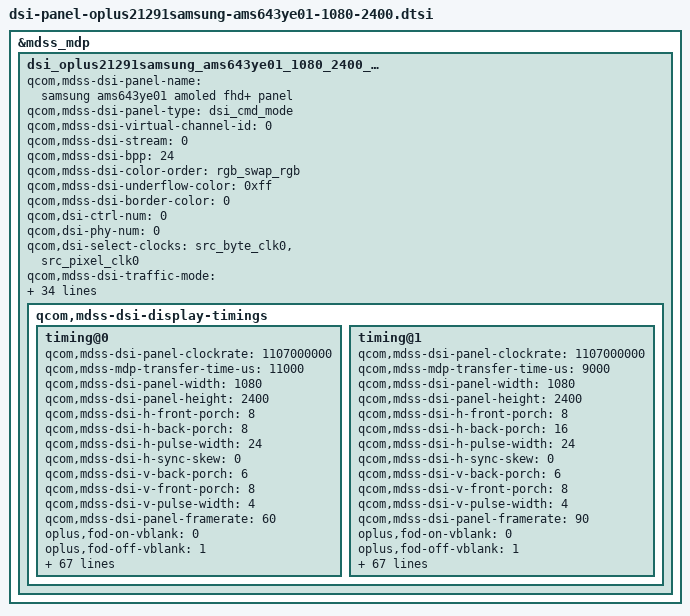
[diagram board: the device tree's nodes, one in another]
/* Copyright (c) 2014-2018, The Linux Foundation. All rights reserved.
 *
 * This program is free software; you can redistribute it and/or modify
 * it under the terms of the GNU General Public License version 2 and
 * only version 2 as published by the Free Software Foundation.
 *
 * This program is distributed in the hope that it will be useful,
 * but WITHOUT ANY WARRANTY; without even the implied warranty of
 * MERCHANTABILITY or FITNESS FOR A PARTICULAR PURPOSE.  See the
 * GNU General Public License for more details.
 */

&mdss_mdp {
	dsi_oplus21291samsung_ams643ye01_1080_2400_cmd: qcom,mdss_dsi_oplus21291samsung_ams643ye01_1080_2400_cmd {
		qcom,mdss-dsi-panel-name =
		  "samsung ams643ye01 amoled fhd+ panel";
		qcom,mdss-dsi-panel-type = "dsi_cmd_mode";
		qcom,mdss-dsi-virtual-channel-id = <0>;
		qcom,mdss-dsi-stream = <0>;
		qcom,mdss-dsi-bpp = <24>;
		qcom,mdss-dsi-color-order = "rgb_swap_rgb";
		qcom,mdss-dsi-underflow-color = <0xff>;
		qcom,mdss-dsi-border-color = <0>;

		qcom,dsi-ctrl-num = <0>;
		qcom,dsi-phy-num = <0>;
		qcom,dsi-select-clocks = "src_byte_clk0", "src_pixel_clk0";

		qcom,mdss-dsi-traffic-mode = "non_burst_sync_event";
		qcom,mdss-dsi-lane-map = "lane_map_0123";
		qcom,mdss-dsi-bllp-eof-power-mode;
		qcom,mdss-dsi-bllp-power-mode;
		qcom,mdss-dsi-lane-0-state;
		qcom,mdss-dsi-lane-1-state;
		qcom,mdss-dsi-lane-2-state;
		qcom,mdss-dsi-lane-3-state;
		qcom,mdss-dsi-dma-trigger = "trigger_sw";
		qcom,mdss-dsi-mdp-trigger = "none";
		qcom,mdss-dsi-reset-sequence = <1 10>, <0 10>, <1 10>;
		qcom,mdss-dsi-te-pin-select = <1>;
		qcom,mdss-dsi-te-dcs-command = <1>;
		qcom,mdss-dsi-te-check-enable;
		qcom,mdss-dsi-te-using-te-pin;
		qcom,mdss-dsi-wr-mem-start = <0x2c>;
		qcom,mdss-dsi-wr-mem-continue = <0x3c>;
		qcom,mdss-dsi-panel-hdr-enabled;
		qcom,mdss-dsi-panel-hdr-color-primaries = <15000 15500 34000
			16000 13250 34500 7500 3000>;
		qcom,mdss-dsi-panel-peak-brightness = <4300000>;
		qcom,mdss-dsi-panel-blackness-level = <1023>;
		qcom,mdss-pan-physical-width-dimension = <68>;
		qcom,mdss-pan-physical-height-dimension = <152>;
		qcom,esd-check-enabled;
		qcom,mdss-dsi-panel-status-check-mode = "reg_read";
		qcom,mdss-dsi-panel-status-command = [06 01 00 01 00 00 02 0A 00
							06 01 00 01 00 00 02 0E 00
							06 01 00 01 00 00 02 05 00];
		qcom,mdss-dsi-panel-status-command-state = "dsi_hs_mode";
		qcom,mdss-dsi-panel-status-value = <0x9F 0x80 0x00>;
		qcom,mdss-dsi-panel-status-read-length = <1 1 1>;

		qcom,mdss-dsi-display-timings {
			timing@0{
				qcom,mdss-dsi-panel-clockrate = <1107000000>;
				qcom,mdss-mdp-transfer-time-us = <11000>;
				qcom,mdss-dsi-panel-width = <1080>;
				qcom,mdss-dsi-panel-height = <2400>;
				qcom,mdss-dsi-h-front-porch = <8>;
				qcom,mdss-dsi-h-back-porch = <8>;
				qcom,mdss-dsi-h-pulse-width = <24>;
				qcom,mdss-dsi-h-sync-skew = <0>;
				qcom,mdss-dsi-v-back-porch = <6>;
				qcom,mdss-dsi-v-front-porch = <8>;
				qcom,mdss-dsi-v-pulse-width = <4>;
				qcom,mdss-dsi-panel-framerate = <60>;
				oplus,fod-on-vblank = <0>;
				oplus,fod-off-vblank = <1>;

				qcom,mdss-dsi-on-command = [
					/*PPS Setting*/
					39 01 00 00 00 00 81 9E
					11 00 00 89 30 80 09 60
					04 38 00 1E 02 1C 02 1C
					02 00 02 0E 00 20 02 E3
					00 07 00 0C 03 50 03 64
					18 00 10 F0 03 0C 20 00
					06 0B 0B 33 0E 1C 2A 38
					46 54 62 69 70 77 79 7B
					7D 7E 01 02 01 00 09 40
					09 BE 19 FC 19 FA 19 F8
					1A 38 1A 78 1A B6 2A F6
					2B 34 2B 74 3B 74 6B F4
					00 00 00 00 00 00 00 00
					00 00 00 00 00 00 00 00
					00 00 00 00 00 00 00 00
					00 00 00 00 00 00 00 00
					00 00 00 00 00 00 00 00
					15 01 00 00 00 00 02 C2 14
					15 01 00 00 00 00 02 9D 01
					/*OSC 167M*/
					39 01 00 00 00 00 03 F0 5A 5A
					39 01 00 00 00 00 03 FC 5A 5A
					39 01 00 00 00 00 03 B0 66 C5
					39 01 00 00 00 00 03 C5 00 8C
					39 01 00 00 00 00 03 B0 2A C5
					39 01 00 00 00 00 05 C5 0D 10 80 45
					39 01 00 00 00 00 03 B0 3E C5
					39 01 00 00 00 00 03 C5 4D 3D
					39 01 00 00 00 00 03 F0 A5 A5
					39 01 00 00 00 00 03 FC A5 A5
					05 01 00 00 80 00 01 11
					/* CASET/PASET Setting */
					39 01 00 00 00 00 05 2A 00 00 04 37
					39 01 00 00 00 00 05 2B 00 00 09 5F
					/* FQ CON Setting*/
					39 01 00 00 00 00 03 F0 5A 5A
					39 01 00 00 00 00 03 B0 27 F2
					15 01 00 00 00 00 02 F2 00
					39 01 00 00 00 00 03 F0 A5 A5
					/* TE vsync ON */
					15 01 00 00 00 00 02 35 00
					/*Frequency Change*/
					39 01 00 00 00 00 03 F0 5A 5A
					39 01 00 00 00 00 03 60 00 00
					39 01 00 00 00 00 02 F7 0F
					39 01 00 00 00 00 03 F0 A5 A5
					15 01 00 00 00 00 02 53 20
				];
				qcom,mdss-dsi-post-on-backlight = [
					39 01 00 00 00 00 03 F0 5A 5A
					39 01 00 00 12 00 03 F0 A5 A5
					/* Display On*/
					05 01 00 00 00 00 01 29
				];
				qcom,mdss-dsi-timing-switch-command = [
					/* 60hz Transition */
					39 01 00 00 00 00 03 F0 5A 5A
					39 01 00 00 00 00 03 60 00 00
					39 01 00 00 00 00 02 F7 0F
					39 01 00 00 00 00 03 F0 A5 A5
				];
				qcom,mdss-dsi-off-command = [
					05 01 00 00 0A 00 01 28
					05 01 00 00 96 00 01 10
				];
				qcom,mdss-dsi-lp1-command = [
					05 01 00 00 25 00 01 28
					39 01 00 00 00 00 03 F0 5A 5A
					39 01 00 00 00 00 02 91 01
					15 01 00 00 00 00 02 53 25
					15 01 00 00 00 00 02 BB 1D
					39 01 00 00 00 00 03 F0 A5 A5
				];
				qcom,mdss-dsi-nolp-command = [
					/*HBM OFF */
					39 00 00 00 00 00 03 F0 5A 5A
					39 00 00 00 00 00 03 B0 02 90
					15 00 00 00 00 00 02 90 1C
					39 00 00 00 00 00 02 91 02
					15 00 00 00 00 00 02 53 20
					39 01 00 00 00 00 03 F0 A5 A5
				];
				qcom,mdss-dsi-aod-high-mode-command = [
					15 01 00 00 00 00 02 53 24
				];
				qcom,mdss-dsi-aod-low-mode-command = [
					15 01 00 00 00 00 02 53 25
				];
				qcom,mdss-dsi-aod-hbm-on-command = [
					/* AOD off */
					39 00 00 00 00 00 03 F0 5A 5A
					39 00 00 00 00 00 02 91 02
					15 00 00 00 00 00 02 53 20
					39 00 00 00 00 00 03 F0 A5 A5
					/* HBM Mode ON */
					39 00 00 00 00 00 03 F0 5A 5A
					39 00 00 00 00 00 03 B0 02 90
					15 00 00 00 00 00 02 90 14
					/* 0xE0 Normal transition */
					39 00 00 00 00 00 02 53 E0
					39 00 00 00 00 00 03 51 0F FF
					39 01 00 00 00 00 03 F0 A5 A5
				];
				qcom,mdss-dsi-hbm-on-command = [
					/* HBM Mode ON */
					39 01 00 00 00 00 03 F0 5A 5A
					39 01 00 00 00 00 03 B0 02 90
					15 01 00 00 00 00 02 90 14
					/* 0xE0 Normal transition */
					39 01 00 00 00 00 02 53 E0
					39 01 00 00 00 00 03 51 0F FF
					39 01 00 00 00 00 03 F0 A5 A5
				];
				qcom,mdss-dsi-normal-hbm-on-command = [
					/* HBM Mode ON */
					39 01 00 00 00 00 03 F0 5A 5A
					39 01 00 00 00 00 03 B0 02 90
					15 01 00 00 00 00 02 90 14
					/* 0xE0 Normal transition */
					39 01 00 00 00 00 02 53 E0
					39 01 00 00 00 00 03 51 0F FF
					39 01 00 00 00 00 03 F0 A5 A5
				];
				qcom,mdss-dsi-hbm-off-command = [
					/*HBM OFF */
					39 01 00 00 00 00 03 F0 5A 5A
					39 01 00 00 00 00 03 B0 02 90
					15 01 00 00 00 00 02 90 1C
					15 01 00 00 00 00 02 53 20
					39 01 00 00 00 00 03 F0 A5 A5
				];
				qcom,mdss-dsi-aod-hbm-off-command = [
					/*HBM OFF */
					39 01 00 00 00 00 03 F0 5A 5A
					39 01 00 00 00 00 03 B0 02 90
					15 01 00 00 00 00 02 90 1C
					15 01 00 00 00 00 02 53 24
					39 01 00 00 00 00 03 F0 A5 A5
					/*AOD on */
					39 01 00 00 00 00 03 F0 5A 5A
					39 01 00 00 00 00 02 91 01
					15 01 00 00 00 00 02 53 24
					15 01 00 00 00 00 02 BB 1D
					39 01 00 00 00 00 03 F0 A5 A5
				];
				qcom,mdss-dsi-seed-off-command = [
					/* CRC OFF */
					39 00 00 00 00 00 03 F0 5A 5A
					15 00 00 00 00 00 02 5D 00
					39 00 00 00 00 00 02 62 01
					39 01 00 00 00 00 03 F0 A5 A5
				];
				qcom,mdss-dsi-seed-0-command = [
					/* SEED CRC Setting */
					39 00 00 00 00 00 03 F0 5A 5A
					39 00 00 00 00 00 02 5D 86
					/* SEED CRC ON */
					39 00 00 00 00 00 02 62 00
					/* SEED CRC DCI-P3 */
					39 00 00 00 00 00 03 B0 2B 62
					39 00 00 00 00 00 16 62 D8 00 04 00 FF 02 00 00 FF 18 FF E4 FB 00 F0 F6 EA 01 FF FF FF
					39 01 00 00 00 00 03 F0 A5 A5
				];
				qcom,mdss-dsi-seed-1-command = [
					/* SEED CRC Setting */
					39 00 00 00 00 00 03 F0 5A 5A
					39 00 00 00 00 00 02 5D 06
					/* SEED CRC ON */
					39 00 00 00 00 00 02 62 00
					/* SEED CRC sRGB */
					39 00 00 00 00 00 03 B0 01 62
					39 00 00 00 00 00 16 62 B0 02 06 3A D7 17 07 05 B2 48 F2 DC C4 07 C8 E9 E9 1D FF FF FF
					39 01 00 00 00 00 03 F0 A5 A5
				];
				qcom,mdss-dsi-seed-2-command = [
					/* SEED CRC Setting */
					39 00 00 00 00 00 03 F0 5A 5A
					39 00 00 00 00 00 02 5D 46
					/* SEED CRC ON */
					39 00 00 00 00 00 02 62 00
					/* SEED CRC Adobe */
					39 00 00 00 00 00 03 B0 16 62
					39 00 00 00 00 00 16 62 D8 00 04 00 FF 02 00 00 FF 18 FF E4 FB 00 F0 F6 EA 01 FF FF FF
					39 01 00 00 00 00 03 F0 A5 A5
				];
				qcom,mdss-dsi-osc-clk-mode0-command = [
					/*OSC 167M*/
					39 01 00 00 00 00 03 F0 5A 5A
					39 01 00 00 00 00 03 FC 5A 5A
					39 01 00 00 00 00 03 B0 66 C5
					39 01 00 00 00 00 03 C5 00 8C
					39 01 00 00 00 00 03 B0 2A C5
					39 01 00 00 00 00 05 C5 0D 10 80 45
					39 01 00 00 00 00 03 B0 3E C5
					39 01 00 00 00 00 03 C5 4D 3D
					39 01 00 00 00 00 03 F0 A5 A5
					39 01 00 00 00 00 03 FC A5 A5
				];
				qcom,mdss-dsi-osc-clk-mode1-command = [
					/*OSC 169M*/
					39 01 00 00 00 00 03 F0 5A 5A
					39 01 00 00 00 00 03 FC 5A 5A
					39 01 00 00 00 00 03 B0 66 C5
					39 01 00 00 00 00 03 C5 00 8C
					39 01 00 00 00 00 03 B0 2A C5
					39 01 00 00 00 00 05 C5 0D 10 80 45
					39 01 00 00 00 00 03 B0 3E C5
					39 01 00 00 00 00 03 C5 4E 2A
					39 01 00 00 00 00 03 F0 A5 A5
					39 01 00 00 00 00 03 FC A5 A5
				];
				qcom,mdss-dsi-hbm-enter-switch-command = [
					39 01 00 00 00 00 03 F0 5A 5A
					39 01 00 00 11 00 03 51 07 FF
					39 01 00 00 00 00 03 91 02 00
					15 00 00 00 00 00 02 53 E0
					39 01 00 00 00 00 03 51 08 00
					39 01 00 00 00 00 03 F0 A5 A5
				];
				qcom,mdss-dsi-hbm-exit-switch-command = [
					39 01 00 00 00 00 03 F0 5A 5A
					15 00 00 00 00 00 02 53 20
					39 01 00 00 11 00 03 51 07 FF
					39 00 00 00 00 00 03 91 02 01
					39 01 00 00 00 00 03 F0 A5 A5
				];

				qcom,mdss-dsi-aod-hbm-on-command-state = "dsi_hs_mode";
				qcom,mdss-dsi-aod-hbm-off-command-state = "dsi_hs_mode";
				qcom,mdss-dsi-seed-off-command-state = "dsi_hs_mode";
				qcom,mdss-dsi-seed-0-command-state = "dsi_hs_mode";
				qcom,mdss-dsi-seed-1-command-state = "dsi_hs_mode";
				qcom,mdss-dsi-seed-2-command-state = "dsi_hs_mode";
				qcom,mdss-dsi-lp1-command-state = "dsi_hs_mode";
				qcom,mdss-dsi-nolp-command-state = "dsi_hs_mode";
				qcom,mdss-dsi-post-on-backlight-state = "dsi_hs_mode";
				qcom,mdss-dsi-on-command-state = "dsi_hs_mode";
				qcom,mdss-dsi-off-command-state = "dsi_hs_mode";
				qcom,compression-mode = "dsc";
				qcom,mdss-dsc-slice-height = <30>;
				qcom,mdss-dsc-slice-width = <540>;
				qcom,mdss-dsc-slice-per-pkt = <2>;
				qcom,mdss-dsc-bit-per-component = <8>;
				qcom,mdss-dsc-bit-per-pixel = <8>;
				qcom,mdss-dsc-block-prediction-enable;
			};

			timing@1{
				qcom,mdss-dsi-panel-clockrate = <1107000000>;
				qcom,mdss-mdp-transfer-time-us = <9000>;
				qcom,mdss-dsi-panel-width = <1080>;
				qcom,mdss-dsi-panel-height = <2400>;
				qcom,mdss-dsi-h-front-porch = <8>;
				qcom,mdss-dsi-h-back-porch = <16>;
				qcom,mdss-dsi-h-pulse-width = <24>;
				qcom,mdss-dsi-h-sync-skew = <0>;
				qcom,mdss-dsi-v-back-porch = <6>;
				qcom,mdss-dsi-v-front-porch = <8>;
				qcom,mdss-dsi-v-pulse-width = <4>;
				qcom,mdss-dsi-panel-framerate = <90>;
				oplus,fod-on-vblank = <0>;
				oplus,fod-off-vblank = <1>;
				qcom,mdss-dsi-on-command = [
					/*PPS Setting*/
					39 01 00 00 00 00 81 9E
					11 00 00 89 30 80 09 60
					04 38 00 1E 02 1C 02 1C
					02 00 02 0E 00 20 02 E3
					00 07 00 0C 03 50 03 64
					18 00 10 F0 03 0C 20 00
					06 0B 0B 33 0E 1C 2A 38
					46 54 62 69 70 77 79 7B
					7D 7E 01 02 01 00 09 40
					09 BE 19 FC 19 FA 19 F8
					1A 38 1A 78 1A B6 2A F6
					2B 34 2B 74 3B 74 6B F4
					00 00 00 00 00 00 00 00
					00 00 00 00 00 00 00 00
					00 00 00 00 00 00 00 00
					00 00 00 00 00 00 00 00
					00 00 00 00 00 00 00 00
					15 01 00 00 00 00 02 C2 14
					15 01 00 00 00 00 02 9D 01
					/*OSC 167M*/
					39 01 00 00 00 00 03 F0 5A 5A
					39 01 00 00 00 00 03 FC 5A 5A
					39 01 00 00 00 00 03 B0 66 C5
					39 01 00 00 00 00 03 C5 00 8C
					39 01 00 00 00 00 03 B0 2A C5
					39 01 00 00 00 00 05 C5 0D 10 80 45
					39 01 00 00 00 00 03 B0 3E C5
					39 01 00 00 00 00 03 C5 4D 3D
					39 01 00 00 00 00 03 F0 A5 A5
					39 01 00 00 00 00 03 FC A5 A5
					05 01 00 00 80 00 01 11
					/* CASET/PASET Setting */
					39 01 00 00 00 00 05 2A 00 00 04 37
					39 01 00 00 00 00 05 2B 00 00 09 5F
					/* FQ CON Setting*/
					39 01 00 00 00 00 03 F0 5A 5A
					39 01 00 00 00 00 03 B0 27 F2
					15 01 00 00 00 00 02 F2 00
					39 01 00 00 00 00 03 F0 A5 A5
					/* TE vsync ON */
					15 01 00 00 00 00 02 35 00
					/*Frequency Change*/
					39 01 00 00 00 00 03 F0 5A 5A
					39 01 00 00 00 00 03 60 08 00
					39 01 00 00 00 00 02 F7 0F
					39 01 00 00 00 00 03 F0 A5 A5
					15 01 00 00 00 00 02 53 20
				];
				qcom,mdss-dsi-post-on-backlight = [
					/* Display On*/
					05 01 00 00 00 00 01 29
				];
				qcom,mdss-dsi-timing-switch-command = [
					/* 90hz Transition */
					39 01 00 00 00 00 03 F0 5A 5A
					39 01 00 00 00 00 03 60 08 00
					39 01 00 00 00 00 02 F7 0F
					39 01 00 00 00 00 03 F0 A5 A5
				];
				qcom,mdss-dsi-off-command = [
					05 01 00 00 0A 00 01 28
					05 01 00 00 96 00 01 10
				];
				qcom,mdss-dsi-lp1-command = [
					05 01 00 00 25 00 01 28
					39 01 00 00 00 00 03 F0 5A 5A
					39 01 00 00 00 00 02 91 01
					15 01 00 00 00 00 02 53 25
					15 01 00 00 00 00 02 BB 1D
					39 01 00 00 00 00 03 F0 A5 A5
				];
				qcom,mdss-dsi-nolp-command = [
					/*HBM OFF */
					39 00 00 00 00 00 03 F0 5A 5A
					39 00 00 00 00 00 03 B0 02 90
					15 00 00 00 00 00 02 90 1C
					39 00 00 00 00 00 02 91 02
					15 00 00 00 00 00 02 53 20
					39 01 00 00 00 00 03 F0 A5 A5
				];
				qcom,mdss-dsi-aod-high-mode-command = [
					15 01 00 00 00 00 02 53 24
				];
				qcom,mdss-dsi-aod-low-mode-command = [
					15 01 00 00 00 00 02 53 25
				];
				qcom,mdss-dsi-aod-hbm-on-command = [
					/* AOD off */
					39 00 00 00 00 00 03 F0 5A 5A
					39 00 00 00 00 00 02 91 02
					15 00 00 00 00 00 02 53 20
					39 00 00 00 00 00 03 F0 A5 A5
					/* HBM Mode ON */
					39 00 00 00 00 00 03 F0 5A 5A
					39 00 00 00 00 00 03 B0 02 90
					15 00 00 00 00 00 02 90 14
					/* 0xE0 Normal transition */
					39 00 00 00 00 00 02 53 E0
					39 00 00 00 00 00 03 51 0F FF
					39 01 00 00 00 00 03 F0 A5 A5
				];
				qcom,mdss-dsi-hbm-on-command = [
					/* HBM Mode ON */
					39 01 00 00 00 00 03 F0 5A 5A
					39 01 00 00 00 00 03 B0 02 90
					15 01 00 00 00 00 02 90 14
					/* 0xE0 Normal transition */
					39 01 00 00 00 00 02 53 E0
					39 01 00 00 00 00 03 51 0F FF
					39 01 00 00 00 00 03 F0 A5 A5
				];
				qcom,mdss-dsi-normal-hbm-on-command = [
					/* HBM Mode ON */
					39 01 00 00 00 00 03 F0 5A 5A
					39 01 00 00 00 00 03 B0 02 90
					15 01 00 00 00 00 02 90 14
					/* 0xE0 Normal transition */
					39 01 00 00 00 00 02 53 E0
					39 01 00 00 00 00 03 51 0F FF
					39 01 00 00 00 00 03 F0 A5 A5
				];
				qcom,mdss-dsi-hbm-off-command = [
					39 01 00 00 00 00 03 F0 5A 5A
					39 01 00 00 00 00 03 B0 02 90
					15 01 00 00 00 00 02 90 1C
					39 01 00 00 00 00 02 91 02
					15 01 00 00 00 00 02 53 20
					39 01 00 00 00 00 03 F0 A5 A5
				];
				qcom,mdss-dsi-aod-hbm-off-command = [
					/*HBM OFF */
					39 01 00 00 00 00 03 F0 5A 5A
					39 01 00 00 00 00 03 B0 02 90
					15 01 00 00 00 00 02 90 1C
					15 01 00 00 00 00 02 53 25
					39 01 00 00 00 00 03 F0 A5 A5
					/*AOD on */
					39 01 00 00 00 00 03 F0 5A 5A
					39 01 00 00 00 00 02 91 01
					15 01 00 00 00 00 02 53 25
					15 01 00 00 00 00 02 BB 1D
					39 01 00 00 00 00 03 F0 A5 A5
				];
				qcom,mdss-dsi-seed-off-command = [
					/* CRC OFF */
					39 00 00 00 00 00 03 F0 5A 5A
					15 00 00 00 00 00 02 5D 00
					39 00 00 00 00 00 02 62 01
					39 01 00 00 00 00 03 F0 A5 A5
				];
				qcom,mdss-dsi-seed-0-command = [
					/* SEED CRC Setting */
					39 00 00 00 00 00 03 F0 5A 5A
					39 00 00 00 00 00 02 5D 86
					/* SEED CRC ON */
					39 00 00 00 00 00 02 62 00
					/* SEED CRC DCI-P3 */
					39 00 00 00 00 00 03 B0 2B 62
					39 00 00 00 00 00 16 62 D8 00 04 00 FF 02 00 00 FF 18 FF E4 FB 00 F0 F6 EA 01 FF FF FF
					39 01 00 00 00 00 03 F0 A5 A5
				];
				qcom,mdss-dsi-seed-1-command = [
					/* SEED CRC Setting */
					39 00 00 00 00 00 03 F0 5A 5A
					39 00 00 00 00 00 02 5D 06
					/* SEED CRC ON */
					39 00 00 00 00 00 02 62 00
					/* SEED CRC sRGB */
					39 00 00 00 00 00 03 B0 01 62
					39 00 00 00 00 00 16 62 B0 02 06 3A D7 17 07 05 B2 48 F2 DC C4 07 C8 E9 E9 1D FF FF FF
					39 01 00 00 00 00 03 F0 A5 A5
				];
				qcom,mdss-dsi-seed-2-command = [
					/* SEED CRC Setting */
					39 00 00 00 00 00 03 F0 5A 5A
					39 00 00 00 00 00 02 5D 46
					/* SEED CRC ON */
					39 00 00 00 00 00 02 62 00
					/* SEED CRC Adobe */
					39 00 00 00 00 00 03 B0 16 62
					39 00 00 00 00 00 16 62 D8 00 04 00 FF 02 00 00 FF 18 FF E4 FB 00 F0 F6 EA 01 FF FF FF
					39 01 00 00 00 00 03 F0 A5 A5
				];
				qcom,mdss-dsi-osc-clk-mode0-command = [
					/*OSC 167M*/
					39 01 00 00 00 00 03 F0 5A 5A
					39 01 00 00 00 00 03 FC 5A 5A
					39 01 00 00 00 00 03 B0 66 C5
					39 01 00 00 00 00 03 C5 00 8C
					39 01 00 00 00 00 03 B0 2A C5
					39 01 00 00 00 00 05 C5 0D 10 80 45
					39 01 00 00 00 00 03 B0 3E C5
					39 01 00 00 00 00 03 C5 4D 3D
					39 01 00 00 00 00 03 F0 A5 A5
					39 01 00 00 00 00 03 FC A5 A5
				];
				qcom,mdss-dsi-osc-clk-mode1-command = [
					/*OSC 169M*/
					39 01 00 00 00 00 03 F0 5A 5A
					39 01 00 00 00 00 03 FC 5A 5A
					39 01 00 00 00 00 03 B0 66 C5
					39 01 00 00 00 00 03 C5 00 8C
					39 01 00 00 00 00 03 B0 2A C5
					39 01 00 00 00 00 05 C5 0D 10 80 45
					39 01 00 00 00 00 03 B0 3E C5
					39 01 00 00 00 00 03 C5 4E 2A
					39 01 00 00 00 00 03 F0 A5 A5
					39 01 00 00 00 00 03 FC A5 A5
				];
				qcom,mdss-dsi-hbm-enter-switch-command = [
					39 01 00 00 00 00 03 F0 5A 5A
					39 01 00 00 0C 00 03 51 07 FF
					39 01 00 00 00 00 03 91 02 00
					15 00 00 00 00 00 02 53 E0
					39 01 00 00 00 00 03 51 08 00
					39 01 00 00 00 00 03 F0 A5 A5
				];
				qcom,mdss-dsi-hbm-exit-switch-command = [
					39 01 00 00 00 00 03 F0 5A 5A
					15 00 00 00 00 00 02 53 20
					39 01 00 00 0C 00 03 51 07 FF
					39 00 00 00 00 00 03 91 02 01
					39 01 00 00 00 00 03 F0 A5 A5
				];

				qcom,mdss-dsi-aod-hbm-on-command-state = "dsi_hs_mode";
				qcom,mdss-dsi-aod-hbm-off-command-state = "dsi_hs_mode";
				qcom,mdss-dsi-seed-off-command-state = "dsi_hs_mode";
				qcom,mdss-dsi-seed-0-command-state = "dsi_hs_mode";
				qcom,mdss-dsi-seed-1-command-state = "dsi_hs_mode";
				qcom,mdss-dsi-seed-2-command-state = "dsi_hs_mode";
				qcom,mdss-dsi-lp1-command-state = "dsi_hs_mode";
				qcom,mdss-dsi-nolp-command-state = "dsi_hs_mode";
				qcom,mdss-dsi-post-on-backlight-state = "dsi_hs_mode";
				qcom,mdss-dsi-on-command-state = "dsi_hs_mode";
				qcom,mdss-dsi-off-command-state = "dsi_hs_mode";
				qcom,compression-mode = "dsc";
				qcom,mdss-dsc-slice-height = <30>;
				qcom,mdss-dsc-slice-width = <540>;
				qcom,mdss-dsc-slice-per-pkt = <2>;
				qcom,mdss-dsc-bit-per-component = <8>;
				qcom,mdss-dsc-bit-per-pixel = <8>;
				qcom,mdss-dsc-block-prediction-enable;
			};
		};
	};
};

